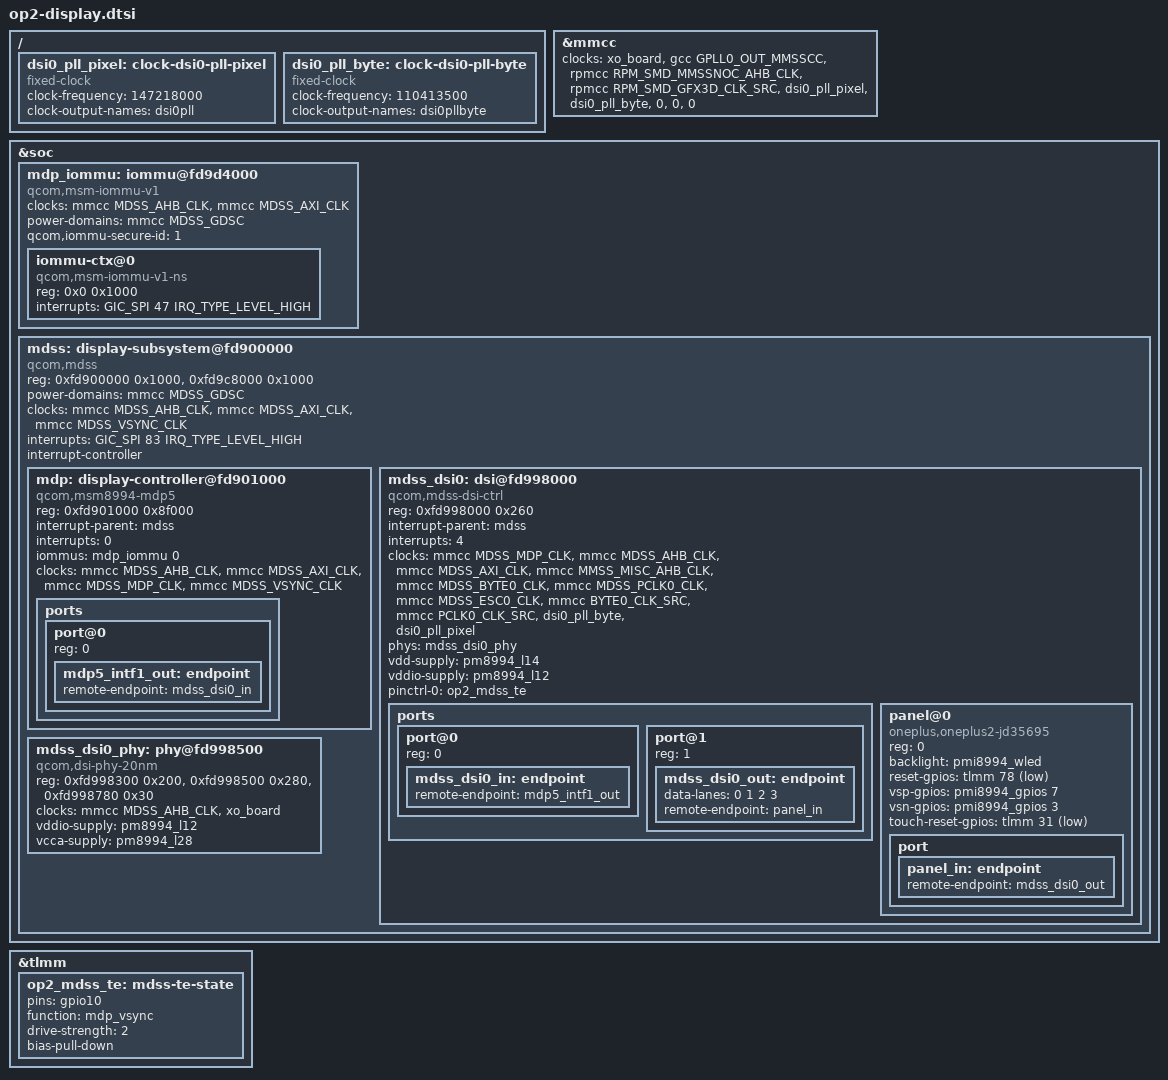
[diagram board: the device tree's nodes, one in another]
// SPDX-License-Identifier: GPL-2.0-only
/*
 * OnePlus 2 display through mainline MDP5 + DSI, taking over the bootloader's
 * DSI0 PLL.
 *
 * Mainline has the msm8994 DSI 20nm PHY but no 20nm DSI PLL. The bootloader
 * leaves the PLL running for this panel (byte0 and pclk0 RCGs fed straight
 * from it, divider 1, read back from MMCC 0x2000/0x2120). So the PLL outputs
 * are described as fixed clocks at the rates this panel mode needs, and the
 * DSI host / MMCC never reprogram the PLL itself.
 *   panel: 1080x1920 @ 60, h 1080+100+8+82, v 1920+3+2+7, 4 lanes, 24 bpp
 *   pixel = 1270 * 1932 * 60 = 147218 kHz; byte = pixel * 24 / 8 / 4
 * Addresses from downstream msm8994-mdss.dtsi / msm8994-mdss-pll.dtsi.
 */

/ {
	dsi0_pll_pixel: clock-dsi0-pll-pixel {
		compatible = "fixed-clock";
		#clock-cells = <0>;
		clock-frequency = <147218000>;
		clock-output-names = "dsi0pll";
	};

	dsi0_pll_byte: clock-dsi0-pll-byte {
		compatible = "fixed-clock";
		#clock-cells = <0>;
		clock-frequency = <110413500>;
		clock-output-names = "dsi0pllbyte";
	};
};

&mmcc {
	clocks = <&xo_board>,
		 <&gcc GPLL0_OUT_MMSSCC>,
		 <&rpmcc RPM_SMD_MMSSNOC_AHB_CLK>,
		 <&rpmcc RPM_SMD_GFX3D_CLK_SRC>,
		 <&dsi0_pll_pixel>,
		 <&dsi0_pll_byte>,
		 <0>,
		 <0>,
		 <0>;
};

&soc {
	/*
	 * MDP SMMU (downstream mdp_iommu_8994, "qcom,msm-smmu-v1", secure id 1):
	 * global part owned by TrustZone, context banks from 0xfd9d4000. Only the
	 * non-secure bank mdp_0 (SID 0, SPI 47) is ours.
	 */
	/*
	 * OP2_MDP_NOIOMMU (Linux 6.12, GPU on a VRAM carveout): no MDP SMMU node, no
	 * iommus, so the whole msm DRM device runs without an MMU and every buffer
	 * comes from the carveout at its physical address, which is what the MDP
	 * and DSI DMA use anyway (they bypass this SMMU, see patch 0004).
	 */
#ifndef OP2_MDP_NOIOMMU
	mdp_iommu: iommu@fd9d4000 {
		compatible = "qcom,msm-iommu-v1";
		ranges = <0 0xfd9d4000 0x3000>;

		clocks = <&mmcc MDSS_AHB_CLK>,
			 <&mmcc MDSS_AXI_CLK>;
		clock-names = "iface",
			      "bus";
		power-domains = <&mmcc MDSS_GDSC>;

		qcom,iommu-secure-id = <1>;

		#address-cells = <1>;
		#size-cells = <1>;
		#iommu-cells = <1>;

		iommu-ctx@0 {
			compatible = "qcom,msm-iommu-v1-ns";
			reg = <0x0 0x1000>;
			interrupts = <GIC_SPI 47 IRQ_TYPE_LEVEL_HIGH>;
		};
	};
#endif

	mdss: display-subsystem@fd900000 {
		compatible = "qcom,mdss";
		reg = <0xfd900000 0x1000>,
		      <0xfd9c8000 0x1000>;
		reg-names = "mdss_phys",
			    "vbif_phys";

		power-domains = <&mmcc MDSS_GDSC>;

		clocks = <&mmcc MDSS_AHB_CLK>,
			 <&mmcc MDSS_AXI_CLK>,
			 <&mmcc MDSS_VSYNC_CLK>;
		clock-names = "iface",
			      "bus",
			      "vsync";

		interrupts = <GIC_SPI 83 IRQ_TYPE_LEVEL_HIGH>;

		interrupt-controller;
		#interrupt-cells = <1>;

		#address-cells = <1>;
		#size-cells = <1>;
		ranges;

		mdp: display-controller@fd901000 {
			compatible = "qcom,msm8994-mdp5", "qcom,mdp5";
			reg = <0xfd901000 0x8f000>;
			reg-names = "mdp_phys";

			interrupt-parent = <&mdss>;
			interrupts = <0>;

#ifndef OP2_MDP_NOIOMMU
			iommus = <&mdp_iommu 0>;
#endif

			clocks = <&mmcc MDSS_AHB_CLK>,
				 <&mmcc MDSS_AXI_CLK>,
				 <&mmcc MDSS_MDP_CLK>,
				 <&mmcc MDSS_VSYNC_CLK>;
			clock-names = "iface",
				      "bus",
				      "core",
				      "vsync";

			ports {
				#address-cells = <1>;
				#size-cells = <0>;

				port@0 {
					reg = <0>;
					mdp5_intf1_out: endpoint {
						remote-endpoint = <&mdss_dsi0_in>;
					};
				};
			};
		};

		mdss_dsi0: dsi@fd998000 {
			compatible = "qcom,mdss-dsi-ctrl";
			reg = <0xfd998000 0x260>;
			reg-names = "dsi_ctrl";

			interrupt-parent = <&mdss>;
			interrupts = <4>;

			clocks = <&mmcc MDSS_MDP_CLK>,
				 <&mmcc MDSS_AHB_CLK>,
				 <&mmcc MDSS_AXI_CLK>,
				 <&mmcc MMSS_MISC_AHB_CLK>,
				 <&mmcc MDSS_BYTE0_CLK>,
				 <&mmcc MDSS_PCLK0_CLK>,
				 <&mmcc MDSS_ESC0_CLK>,
				 <&mmcc BYTE0_CLK_SRC>,
				 <&mmcc PCLK0_CLK_SRC>,
				 <&dsi0_pll_byte>,
				 <&dsi0_pll_pixel>;
			clock-names = "mdp_core",
				      "iface",
				      "bus",
				      "core_mmss",
				      "byte",
				      "pixel",
				      "core",
				      "byte_src",
				      "pixel_src",
				      "dsi_pll_byte",
				      "dsi_pll_pixel";

			phys = <&mdss_dsi0_phy>;

			/* OnePlus: vdd L14, vddio L12 (LAB/IBB not used: external bias IC) */
			vdd-supply = <&pm8994_l14>;
			vddio-supply = <&pm8994_l12>;

			pinctrl-names = "default";
			pinctrl-0 = <&op2_mdss_te>;

			#address-cells = <1>;
			#size-cells = <0>;

			ports {
				#address-cells = <1>;
				#size-cells = <0>;

				port@0 {
					reg = <0>;
					mdss_dsi0_in: endpoint {
						remote-endpoint = <&mdp5_intf1_out>;
					};
				};

				port@1 {
					reg = <1>;
					mdss_dsi0_out: endpoint {
						data-lanes = <0 1 2 3>;
						remote-endpoint = <&panel_in>;
					};
				};
			};

			panel@0 {
				compatible = "oneplus,oneplus2-jd35695";
				reg = <0>;

				backlight = <&pmi8994_wled>;
				reset-gpios = <&tlmm 78 GPIO_ACTIVE_LOW>;
				/* TPS65132 bias enables, as OnePlus's lcd-poweron-en(-n) */
				vsp-gpios = <&pmi8994_gpios 7 GPIO_ACTIVE_HIGH>;
				vsn-gpios = <&pmi8994_gpios 3 GPIO_ACTIVE_HIGH>;
				/* in-cell touch reset, pulsed after the panel is on */
				touch-reset-gpios = <&tlmm 31 GPIO_ACTIVE_LOW>;

				port {
					panel_in: endpoint {
						remote-endpoint = <&mdss_dsi0_out>;
					};
				};
			};
		};

		mdss_dsi0_phy: phy@fd998500 {
			compatible = "qcom,dsi-phy-20nm";
			reg = <0xfd998300 0x200>,
			      <0xfd998500 0x280>,
			      <0xfd998780 0x30>;
			reg-names = "dsi_pll",
				    "dsi_phy",
				    "dsi_phy_regulator";

			#clock-cells = <1>;
			#phy-cells = <0>;

			clocks = <&mmcc MDSS_AHB_CLK>,
				 <&xo_board>;
			clock-names = "iface",
				      "ref";

			vddio-supply = <&pm8994_l12>;
			vcca-supply = <&pm8994_l28>;
		};
	};
};

&tlmm {
	/* panel TE into the MDP (downstream mdss_te_active: gpio10 mdp_vsync) */
	op2_mdss_te: mdss-te-state {
		pins = "gpio10";
		function = "mdp_vsync";
		drive-strength = <2>;
		bias-pull-down;
	};
};
